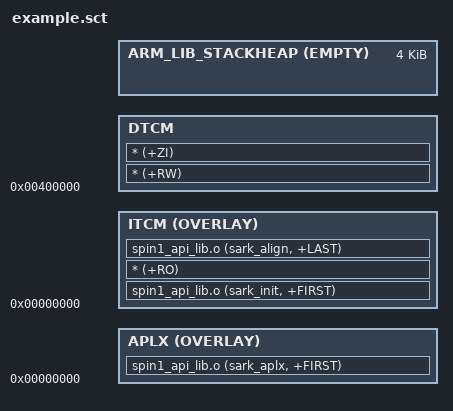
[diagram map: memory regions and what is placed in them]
##
## example.sct	    Scatter load file for "spin1_api" applications
##
## Copyright (C)    The University of Manchester - 2011
##
## Author           Steve Temple, APT Group, School of Computer Science
##
## Email            temples@cs.man.ac.uk
##


APLX_IMAGE 0
{
	APLX 0 OVERLAY
    	{
		spin1_api_lib.o  (sark_aplx, +FIRST)
    	}

      	ITCM 0 OVERLAY
  	{   
    	    	spin1_api_lib.o (sark_init, +FIRST)
    		* (+RO)
		spin1_api_lib.o (sark_align, +LAST)
  	}

  	DTCM 0x00400000
  	{
    		* (+RW)
		* (+ZI)
  	}

	ARM_LIB_STACKHEAP +0x0 EMPTY 0x1000
	{
	
	}
}
